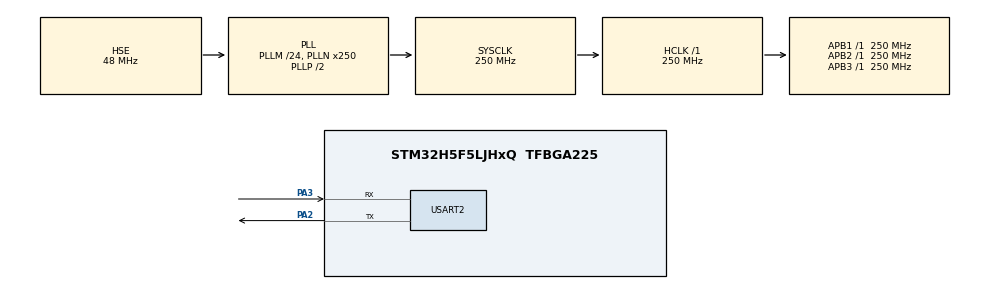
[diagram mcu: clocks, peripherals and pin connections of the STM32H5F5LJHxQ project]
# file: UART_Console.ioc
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CORTEX_M33_NS.userName=CORTEX_M33
Mcu.Family=STM32H5
Mcu.Name=STM32H5F5LJHxQ
Mcu.Package=TFBGA225
NVIC.PriorityGroup=NVIC_PRIORITYGROUP_4
PA2.Mode=Asynchronous
PA2.Signal=USART2_TX
PA3.Mode=Asynchronous
PA3.Signal=USART2_RX
PH0-OSC_IN(PH0).Mode=HSE-External-Oscillator
PH0-OSC_IN(PH0).Signal=RCC_OSC_IN
PH1-OSC_OUT(PH1).Mode=HSE-External-Oscillator
PH1-OSC_OUT(PH1).Signal=RCC_OSC_OUT
ProjectManager.HeapSize=0x200
ProjectManager.StackSize=0x400
ProjectManager.TargetToolchain=EWARM V9.20
RCC.ADCFreq_Value=250000000
RCC.AHBFreq_Value=250000000
RCC.APB1Freq_Value=250000000
RCC.APB1TimFreq_Value=250000000
RCC.APB2Freq_Value=250000000
RCC.APB2TimFreq_Value=250000000
RCC.APB3Freq_Value=250000000
RCC.CSI_VALUE=4000000
RCC.CortexFreq_Value=250000000
RCC.EPOD_VALUE=48000000
RCC.HCLKFreq_Value=250000000
RCC.HSE_VALUE=48000000
RCC.HSI48_VALUE=48000000
RCC.HSI_VALUE=64000000
RCC.LSE_VALUE=32768
RCC.LSIRC_VALUE=32000
RCC.PLLM=24
RCC.PLLN=250
RCC.PLLSourceVirtual=RCC_PLL1_SOURCE_HSE
RCC.SYSCLKFreq_VALUE=250000000
RCC.SYSCLKSource=RCC_SYSCLKSOURCE_PLLCLK
RCC.USBFreq_Value=258000000
RCC.VCOOutputFreq_Value=500000000
USART2.VirtualMode-Asynchronous=VM_ASYNC
VP_CORTEX_M33_NS_VS_Hclk.Mode=Hclk_Mode
VP_ICACHE_VS_ICACHE.Mode=DefaultMode
VP_PWR_VS_LPOM.Mode=PowerOptimisation
VP_PWR_VS_SECSignals.Mode=Security/Privilege
board=custom

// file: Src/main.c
/* USER CODE BEGIN Header */
/**
  ******************************************************************************
  * @file    UART/UART_Console/Src/main.c
  * @author  MCD Application Team
  * @brief   This example shows how to retarget the C library printf function
  *          to the UART.
  ******************************************************************************
  * @attention
  *
  * Copyright (c) 2023 STMicroelectronics.
  * All rights reserved.
  *
  * This software is licensed under terms that can be found in the LICENSE file
  * in the root directory of this software component.
  * If no LICENSE file comes with this software, it is provided AS-IS.
  *
  ******************************************************************************
  */
/* USER CODE END Header */
#include "main.h"

UART_HandleTypeDef huart2;

void SystemClock_Config(void);
static void MX_GPIO_Init(void);
static void MX_ICACHE_Init(void);
static void MX_USART2_UART_Init(void);
/* USER CODE BEGIN PFP */
#if defined(__ICCARM__)
__ATTRIBUTES size_t __write(int, const unsigned char *, size_t);
#endif /* __ICCARM__ */

#if defined(__ICCARM__)
/* New definition from EWARM V9, compatible with EWARM8 */
int iar_fputc(int ch);
#define PUTCHAR_PROTOTYPE int iar_fputc(int ch)
#define GETCHAR_PROTOTYPE int fgetc(FILE *f)
#elif defined ( __CC_ARM ) || defined(__ARMCC_VERSION)
/* ARM Compiler 5/6*/
#define PUTCHAR_PROTOTYPE int fputc(int ch, FILE *f)
#define GETCHAR_PROTOTYPE int fgetc(FILE *f)
#elif defined(__GNUC__)
int __io_putchar(int ch);
#define PUTCHAR_PROTOTYPE int __io_putchar(int ch)
int __io_getchar(void);
#define GETCHAR_PROTOTYPE int __io_getchar(void)
#endif /* __ICCARM__ */

/* USER CODE END PFP */

int main(void)
{

  /* USER CODE BEGIN 1 */

  /* STM32H5xx HAL library initialization:
       - Systick timer is configured by default as source of time base, but user
             can eventually implement his proper time base source (a general purpose
             timer for example or other time source), keeping in mind that Time base
             duration should be kept 1ms since PPP_TIMEOUT_VALUEs are defined and
             handled in milliseconds basis.
       - Set NVIC Group Priority to 4
       - Low Level Initialization
     */
  /* USER CODE END 1 */

  /* MCU Configuration--------------------------------------------------------*/

  /* Reset of all peripherals, Initializes the Flash interface and the Systick. */
  HAL_Init();

  /* Configure the system clock */
  SystemClock_Config();

  /* USER CODE BEGIN SysInit */
  /* Initialize BSP Led for LED3 */
  BSP_LED_Init(LED3);

  /* USER CODE END SysInit */

  /* Initialize all configured peripherals */
  MX_GPIO_Init();
  MX_ICACHE_Init();
  MX_USART2_UART_Init();
  /* USER CODE BEGIN 2 */

  /* Output a message on Hyperterminal using printf function */
  printf("\n\r UART Printf Example: retarget the C library printf function to the UART\n\r");
  printf("** This message is printed using printf() function. ** \n\r");

  /* User is prompted to enter characters on terminal input.
     Entered characters are echoed on terminal output until a CR character is entered */
  printf("\n\r UART Getchar Example: retarget UART input to the C library getchar function\n\r");
  printf("Enter a string then press ENTER \n\r");
  fflush (stdout);

  uint8_t receivedchar;
  receivedchar= ' ';
  while(receivedchar!= '\n' && receivedchar != '\r')
  {
#if defined (__ICCARM__) || defined (__ARMCC_VERSION)
    receivedchar = fgetc(stdin);
#elif defined(__GNUC__)
    receivedchar = __io_getchar();
#endif /* __ICCARM__ || __ARMCC_VERSION */
  }

  /* End of example */
  printf("\n\rEnd of example\n\r");
  fflush (stdout);
  /* USER CODE END 2 */

  /* Infinite loop */
  while (1)
  {

  }
}

void SystemClock_Config(void)
{
  RCC_OscInitTypeDef RCC_OscInitStruct = {0};
  RCC_ClkInitTypeDef RCC_ClkInitStruct = {0};

  /** Configure the main internal regulator output voltage
  */
  __HAL_PWR_VOLTAGESCALING_CONFIG(PWR_REGULATOR_VOLTAGE_SCALE0);

  while(!__HAL_PWR_GET_FLAG(PWR_FLAG_VOSRDY)) {}

  /** Initializes the RCC Oscillators according to the specified parameters
  * in the RCC_OscInitTypeDef structure.
  */
  RCC_OscInitStruct.OscillatorType = RCC_OSCILLATORTYPE_HSE;
  RCC_OscInitStruct.HSEState = RCC_HSE_ON;
  RCC_OscInitStruct.PLL.PLLState = RCC_PLL_ON;
  RCC_OscInitStruct.PLL.PLLSource = RCC_PLL1_SOURCE_HSE;
  RCC_OscInitStruct.PLL.PLLM = 24;
  RCC_OscInitStruct.PLL.PLLN = 250;
  RCC_OscInitStruct.PLL.PLLP = 2;
  RCC_OscInitStruct.PLL.PLLQ = 2;
  RCC_OscInitStruct.PLL.PLLR = 2;
  RCC_OscInitStruct.PLL.PLLRGE = RCC_PLL1_VCIRANGE_1;
  RCC_OscInitStruct.PLL.PLLVCOSEL = RCC_PLL1_VCORANGE_WIDE;
  RCC_OscInitStruct.PLL.PLLFRACN = 0;
  if (HAL_RCC_OscConfig(&RCC_OscInitStruct) != HAL_OK)
  {
    Error_Handler();
  }

  /** Initializes the CPU, AHB and APB buses clocks
  */
  RCC_ClkInitStruct.ClockType = RCC_CLOCKTYPE_HCLK|RCC_CLOCKTYPE_SYSCLK
                              |RCC_CLOCKTYPE_PCLK1|RCC_CLOCKTYPE_PCLK2
                              |RCC_CLOCKTYPE_PCLK3;
  RCC_ClkInitStruct.SYSCLKSource = RCC_SYSCLKSOURCE_PLLCLK;
  RCC_ClkInitStruct.AHBCLKDivider = RCC_SYSCLK_DIV1;
  RCC_ClkInitStruct.APB1CLKDivider = RCC_HCLK_DIV1;
  RCC_ClkInitStruct.APB2CLKDivider = RCC_HCLK_DIV1;
  RCC_ClkInitStruct.APB3CLKDivider = RCC_HCLK_DIV1;

  if (HAL_RCC_ClockConfig(&RCC_ClkInitStruct, FLASH_LATENCY_5) != HAL_OK)
  {
    Error_Handler();
  }

  /** Configure the programming delay
  */
  __HAL_FLASH_SET_PROGRAM_DELAY(FLASH_PROGRAMMING_DELAY_2);
}

static void MX_ICACHE_Init(void)
{

  /** Enable instruction cache (default 2-ways set associative cache)
  */
  if (HAL_ICACHE_Enable() != HAL_OK)
  {
    Error_Handler();
  }

}

static void MX_USART2_UART_Init(void)
{

  huart2.Instance = USART2;
  huart2.Init.BaudRate = 115200;
  huart2.Init.WordLength = UART_WORDLENGTH_8B;
  huart2.Init.StopBits = UART_STOPBITS_1;
  huart2.Init.Parity = UART_PARITY_NONE;
  huart2.Init.Mode = UART_MODE_TX_RX;
  huart2.Init.HwFlowCtl = UART_HWCONTROL_NONE;
  huart2.Init.OverSampling = UART_OVERSAMPLING_16;
  huart2.Init.OneBitSampling = UART_ONE_BIT_SAMPLE_DISABLE;
  huart2.Init.ClockPrescaler = UART_PRESCALER_DIV1;
  huart2.AdvancedInit.AdvFeatureInit = UART_ADVFEATURE_NO_INIT;
  if (HAL_UART_Init(&huart2) != HAL_OK)
  {
    Error_Handler();
  }
  if (HAL_UARTEx_SetTxFifoThreshold(&huart2, UART_TXFIFO_THRESHOLD_1_8) != HAL_OK)
  {
    Error_Handler();
  }
  if (HAL_UARTEx_SetRxFifoThreshold(&huart2, UART_RXFIFO_THRESHOLD_1_8) != HAL_OK)
  {
    Error_Handler();
  }
  if (HAL_UARTEx_DisableFifoMode(&huart2) != HAL_OK)
  {
    Error_Handler();
  }

}

static void MX_GPIO_Init(void)
{

  /* GPIO Ports Clock Enable */
  __HAL_RCC_GPIOH_CLK_ENABLE();

}

/* USER CODE BEGIN 4 */

/**
  * @brief  Retargets the C library printf function to the USART.
  * @param  None
  * @retval None
  */
PUTCHAR_PROTOTYPE
{
  /* Place your implementation of fputc here */
  /* e.g. write a character to the USART1 and Loop until the end of transmission */
  HAL_UART_Transmit(&huart2, (uint8_t *)&ch, 1, 0xFFFF);

  return ch;
}

GETCHAR_PROTOTYPE
{
  uint8_t ch = 0;
  /* Place your implementation of fgetc here */

  /* Clear the Overrun flag just before receiving the first character */
  __HAL_UART_CLEAR_OREFLAG(&huart2);

  /* Wait for reception of a character on the USART1 RX line
     and echo this character on console */
  HAL_UART_Receive(&huart2, (uint8_t *)&ch, 1, 0xFFFF);
  HAL_UART_Transmit(&huart2, (uint8_t *)&ch, 1, 0xFFFF);
  return ch;
}

#if defined(__ICCARM__)
/**
  * @brief  Retargets the C library __write function to the IAR function iar_fputc.
  * @param  file: file descriptor.
  * @param  ptr: pointer to the buffer where the data is stored.
  * @param  len: length of the data to write in bytes.
  * @retval length of the written data in bytes.
  */
size_t __write(int file, unsigned char const *ptr, size_t len)
{
  size_t idx;
  unsigned char const *pdata = ptr;

  for (idx = 0; idx < len; idx++)
  {
    iar_fputc((int)*pdata);
    pdata++;
  }
  return len;
}
#endif /* __ICCARM__ */

/* USER CODE END 4 */

void Error_Handler(void)
{
  /* USER CODE BEGIN Error_Handler_Debug */
  /* User can add his own implementation to report the HAL error return state */
  __disable_irq();
  /* Turn LED3 on */
  BSP_LED_On(LED3);
  while (1)
  {
  }
  /* USER CODE END Error_Handler_Debug */
}
